# APP_CANCFG register map
Vendor: Texas Instruments
Peripheral module from a debugger description file (folder xwrl64xx).
Registers are 32-bit, read-only, no defined reset value unless marked. A register's access mark holds for its fields unless they carry their own. Offsets are as the file gives them; lines under a group give offsets from that group; [hi:lo] are bit positions; {n}, {i} and the like mark numbered series; 'fields as' and 'values as' point back to an identical list; <NAME> marks a mode.

## APP_CANCFG
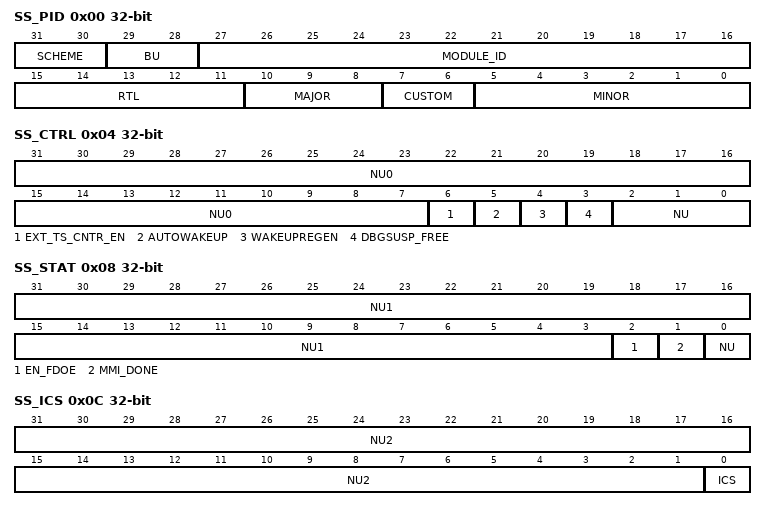
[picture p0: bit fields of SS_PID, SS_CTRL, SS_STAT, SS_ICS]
0x00 SS_PID
  [31:30] SCHEME — PID register scheme
  [29:28] BU — Business Unit: 10 = Processors
  [27:16] MODULE_ID
  [15:11] RTL — RTL revision. Will vary depending on release.
  [10:8] MAJOR — Major revision
  [7:6] CUSTOM
  [5:0] MINOR — Minor revision
0x04 SS_CTRL access per field
  [31:7] NU0 ro — Reserved
  [6] EXT_TS_CNTR_EN rw — External TimeStamp Counter Enable
  [5] AUTOWAKEUP rw — Automatic Wakeup Enable
  [4] WAKEUPREGEN rw — Wakeup Request Enable
  [3] DBGSUSP_FREE rw — 0-Honor Debug Suspend, 1-Disregard debug suspend
  [2:0] NU ro — Reserved
0x08 SS_STAT
  [31:3] NU1 — Reserved
  [2] EN_FDOE — Reflects the value of mcanss_enable_fdoe configuration port x=mcanss_enable_fdoe
  [1] MMI_DONE — 0:Memory Initialization is in progress, 1:Memory Intialization Done
  [0] NU — Reserved
0x0C SS_ICS access per field
  [31:1] NU2 ro — Reserved
  [0] ICS wo — This bit contains the External TimeStamp Counter Overflow Interrupt status. Write '1' to clear bits. (ICS - Interrupt Clear Shadow Register)
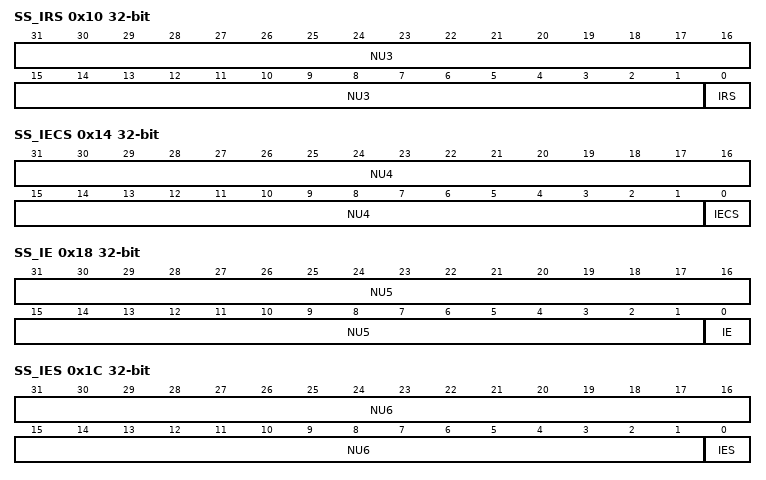
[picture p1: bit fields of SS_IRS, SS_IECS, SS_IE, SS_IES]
0x10 SS_IRS
  [31:1] NU3 — Reserved
  [0] IRS — External TimeStamp Counter Overflow Interrupt status. Read raw interrupt status. (IRS - Interrupt Raw Status Register)
0x14 SS_IECS access per field
  [31:1] NU4 ro — Reserved
  [0] IECS wo — External TimeStamp Counter Overflow Interrupt. Write '1' to clear bits. (IECS - Interrupt Enable Clear Shadow Register)
0x18 SS_IE access per field
  [31:1] NU5 ro — Reserved
  [0] IE rw — External TimeStamp Counter Overflow Interrupt. Write '1' to set interrupt enable. Read returns interrupt enable. (IE - Interrupt Enable Register)
0x1C SS_IES
  [31:1] NU6 — Reserved
  [0] IES — External TimeStamp Counter Overflow Interrupt. Read Enabled Interrupts. (IES - Interrupt Enable Status)
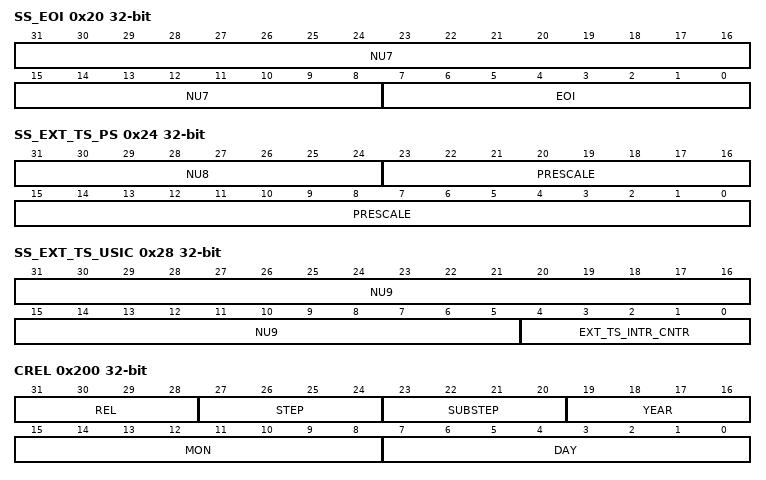
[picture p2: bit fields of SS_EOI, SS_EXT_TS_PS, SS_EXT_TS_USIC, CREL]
0x20 SS_EOI access per field
  [31:8] NU7 ro — Reserved
  [7:0] EOI wo — Write with bit position of targeted interrupt. (E.g. Ext TS is bit 0). Upon write, level interrupt will clear and if unserviced interrupt counter > 1 will issue another pulse interrupt. Field values: ext_ts_eoi(0): EOI value for External TS interrupt mcan_0_eoi(1): EOI value for mcan[0] interrupt mcan_1_eoi(2): EOI value for mcan[1] interrupt (EOI - End Of Interrupt)
0x24 SS_EXT_TS_PS access per field
  [31:24] NU8 ro — Reserved
  [23:0] PRESCALE rw — External Timestamp Prescaler reload value. External Timestamp count rate is host clock rate divided by this value with one exception: a value of 0 has the same effect as 1 .
0x28 SS_EXT_TS_USIC
  [31:5] NU9 — Reserved
  [4:0] EXT_TS_INTR_CNTR — Number of unserviced rollover interrupts. If >1 an EOI write will issue another pulse interrupt (EXT_TS_USIC - External TImeStamp Unserviced Interrupts Counter)
0x200 CREL
  [31:28] REL — Core Release
  [27:24] STEP — Step of Core Release
  [23:20] SUBSTEP — Sub-Step of Core Release
  [19:16] YEAR — Time Stamp Year
  [15:8] MON — Time Stamp Month
  [7:0] DAY — Time Stamp Day
0x204 ENDN
  [31:0] ETV — Endianess test value
0x208 CUST
  [31:0] CUST — Custom
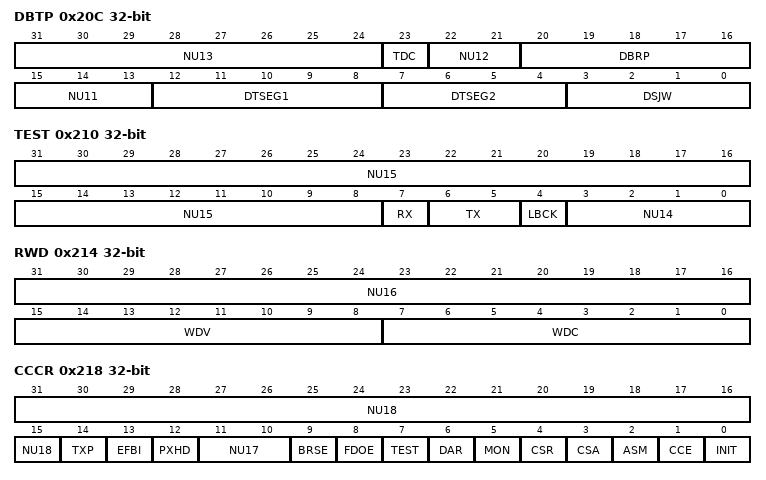
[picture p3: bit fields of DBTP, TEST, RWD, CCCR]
0x20C DBTP access per field
  [31:24] NU13 ro — Reserved
  [23] TDC rw — Transmitter Delay Compensation
  [22:21] NU12 ro — Reserved
  [20:16] DBRP rw — Data Baud Rate Prescaler
  [15:13] NU11 ro — Reserved
  [12:8] DTSEG1 rw — Data time segment before smaple point
  [7:4] DTSEG2 rw — Data time segment after sample point
  [3:0] DSJW rw — Data resynchronization Jump Width
0x210 TEST access per field
  [31:8] NU15 ro — Reserved
  [7] RX ro — Receive Pin
  [6:5] TX rw — Control of Transmit Pin
  [4] LBCK rw — Loop Back Mode
  [3:0] NU14 ro — Reserved
0x214 RWD access per field
  [31:16] NU16 ro — Reserved
  [15:8] WDV ro — Watchdog Value
  [7:0] WDC rw — Watchdog Counter Value
0x218 CCCR access per field
  [31:15] NU18 ro — Reserved
  [14] TXP rw — Transmit Pause
  [13] EFBI rw — Edge Filtering durign Bus Integration
  [12] PXHD rw — Protocol Exception Handling Disable
  [11:10] NU17 ro — Reserved
  [9] BRSE rw — Bit Rate Switch Enable
  [8] FDOE rw — FD Operation Enable
  [7] TEST rw — Test Mode enable
  [6] DAR rw — Disable Automatic Regransmission
  [5] MON rw — Bus Monitoring Mode
  [4] CSR rw — Clock Stop Request
  [3] CSA ro — Clock Stop Acknowledge
  [2] ASM rw — Restriced Operation Mode
  [1] CCE rw — Configuration Change Enable
  [0] INIT rw — Initialization
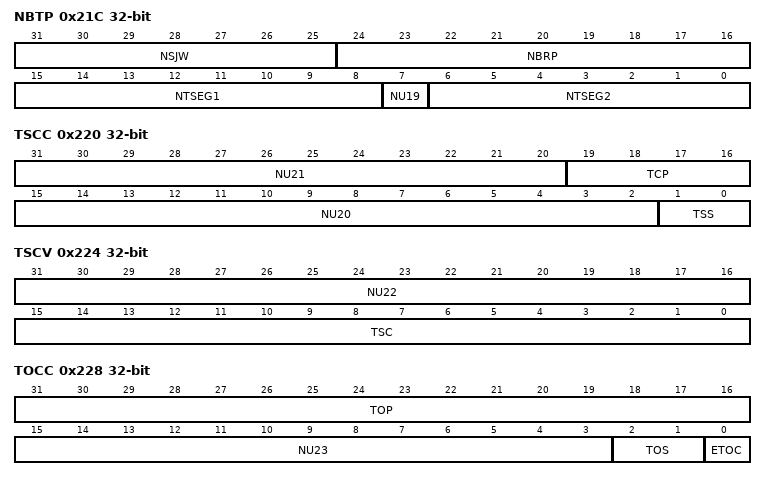
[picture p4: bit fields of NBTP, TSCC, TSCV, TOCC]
0x21C NBTP access per field
  [31:25] NSJW rw — Nominal Resynchronization Jump Width
  [24:16] NBRP rw — Nominal Baud Rate Prescaler
  [15:8] NTSEG1 rw — Nominal Time segment before sample point
  [7] NU19 ro — Reserved
  [6:0] NTSEG2 rw — Nominal Time segment after sample point
0x220 TSCC access per field
  [31:20] NU21 ro — Reserved
  [19:16] TCP rw — Timestamp Counter Prescaler
  [15:2] NU20 ro — Reserved
  [1:0] TSS rw — Timestamp Select
0x224 TSCV access per field
  [31:16] NU22 ro — Reserved
  [15:0] TSC rw — Timestamp Counter
0x228 TOCC access per field
  [31:16] TOP rw — Timeout Period
  [15:3] NU23 ro — Reserved
  [2:1] TOS rw — Timeout Select
  [0] ETOC rw — Enable Timeout Counter
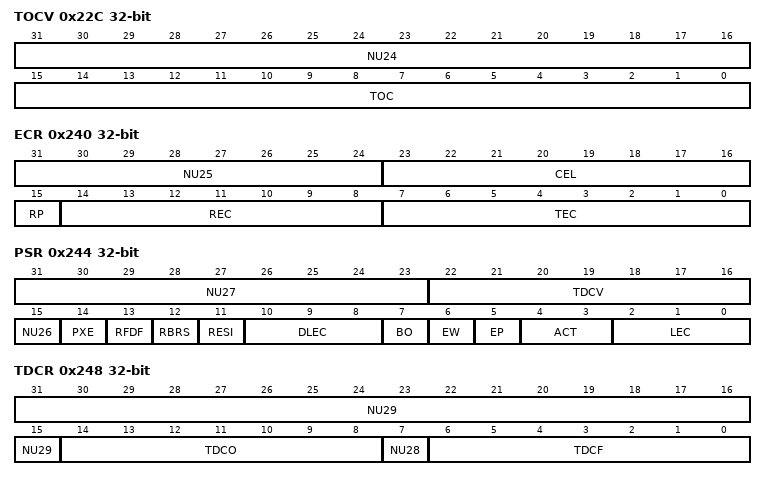
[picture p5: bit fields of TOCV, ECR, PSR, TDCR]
0x22C TOCV access per field
  [31:16] NU24 ro — Reserved
  [15:0] TOC rw — Timeout Counter
{0x230+4i} RES{i:02} (i=0..3)
0x240 ECR
  [31:24] NU25 — Reserved
  [23:16] CEL — CAN Error Logging
  [15] RP — Recieve Error Passive
  [14:8] REC — Recieve Error Counter
  [7:0] TEC — Transmit Error Counter
0x244 PSR
  [31:23] NU27 — Reserved
  [22:16] TDCV — Transmitter Delay Compensation Value
  [15] NU26 — Reserved
  [14] PXE — Protocol Exception Event
  [13] RFDF — Recieved a CAN FD Message
  [12] RBRS — BRS flag of last recieved CAN FD Message
  [11] RESI — ESI flag of last recieved CAN FD Message
  [10:8] DLEC — Data Phase Last Error Code
  [7] BO — Bus_Off status
  [6] EW — Warning Status
  [5] EP — Error Passive
  [4:3] ACT — Activity
  [2:0] LEC — Last Error Code
0x248 TDCR access per field
  [31:15] NU29 ro — Reserved
  [14:8] TDCO rw — Transmitter Delay Compensation Offset
  [7] NU28 ro — Reserved
  [6:0] TDCF rw — Transmitter Delay Compensation Filter Window Length
0x24C RES04
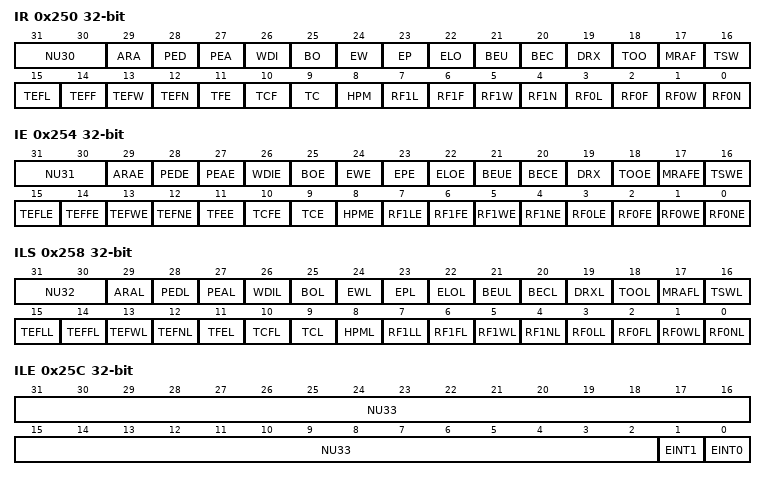
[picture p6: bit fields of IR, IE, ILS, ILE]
0x250 IR access per field
  [31:30] NU30 ro — Reserved
  [29] ARA rw — Access to Reserved Address
  [28] PED rw — Protocol Error in data Phase
  [27] PEA rw — Protocol Error in Arbitration Phase
  [26] WDI rw — Watchdog Interrupt
  [25] BO rw — Bus_Off Status
  [24] EW rw — Warning Status
  [23] EP rw — Error Passive
  [22] ELO rw — Error Logging Overflow
  [21] BEU rw — Bit Error Uncorrected
  [20] BEC rw — Bit Error Corrected
  [19] DRX rw — Message stored to Dedicated Rx Buffer
  [18] TOO rw — Timeout Occurred
  [17] MRAF rw — Message RAM Access Failure
  [16] TSW rw — Timestamp Wraparound
  [15] TEFL rw — Tx Event FIFO Element Lost
  [14] TEFF rw — Tx Event FIFO Full
  [13] TEFW rw — Tx Event FIFO Watermark Reached
  [12] TEFN rw — Tx Event FIFO New Entry
  [11] TFE rw — Tx FIFO Empty
  [10] TCF rw — Transmission Cancellation Finished
  [9] TC rw — Transmission Complete
  [8] HPM rw — High Priority Message
  [7] RF1L rw — Rx FIFO 1 Message Lost
  [6] RF1F rw — Rx FIFO 1 Full
  [5] RF1W rw — Rx FIFO 1 Watermark Reached
  [4] RF1N rw — Rx FIFO 1 New Message
  [3] RF0L rw — Rx FIFO 0 Message Lost
  [2] RF0F rw — Rx FIFO 0 Full
  [1] RF0W rw — Rx FIFO 0 Watermark Reached
  [0] RF0N rw — Rx FIFO 0 New Message
0x254 IE access per field
  [31:30] NU31 ro — Reserved
  [29] ARAE rw — Accees to Reserve Address Interrupt Enable
  [28] PEDE rw — Protocol Error in Data Phase Interrupt Enable
  [27] PEAE rw — Protocol Error in Arbitration Phase Interrupt Enable
  [26] WDIE rw — Watchdog Interrupt Enable
  [25] BOE rw — Bus_Off Status Interrupt Enable
  [24] EWE rw — Warning Status Interrupt Enable
  [23] EPE rw — Error Passive Interrupt Enable
  [22] ELOE rw — Error Logging Overflow Interrupt Enable
  [21] BEUE rw — Bit Error Uncorrected Interrupt Enable
  [20] BECE rw — Bit Error Corrected Interrupt Enable
  [19] DRX rw — Message stored to Dedicated Rx Buffer Interrupt Enable
  [18] TOOE rw — Timeout Occurred Interrupt Enable
  [17] MRAFE rw — Message RAM Access Failure Interrupt Enable
  [16] TSWE rw — Timestamp Wraparound Interrupt Enable
  [15] TEFLE rw — Tx Event FIFO Event Lost Interrupt Enable
  [14] TEFFE rw — Tx Event FIFO Full Interrupt Enable
  [13] TEFWE rw — Tx Event FIFO Watermark Reached Interrupt enable
  [12] TEFNE rw — Tx Event FIFO New Entry Interrupt Enable
  [11] TFEE rw — Tx FIFO Empty Interrupt Enable
  [10] TCFE rw — Transmission Cancellation Finishied Interrupt Enable
  [9] TCE rw — Transmission Completed Interrupt Enable
  [8] HPME rw — High Priority message Interrupt Enable
  [7] RF1LE rw — rx FIFO 1 Message Lost Interrupt Enable
  [6] RF1FE rw — Rx FIFO 1 Full Interrupt Enable
  [5] RF1WE rw — Rx FIFO 1 Watermark Reached Interrupt Enable
  [4] RF1NE rw — Rx FIFO 1 New Message Interrupt Enable
  [3] RF0LE rw — Rx FIFO 0 Message Lost Interrupt Enable
  [2] RF0FE rw — Rx FIFO 0 Full Interrupt Enable
  [1] RF0WE rw — Rx FIFO 0 Watermark Reached Interrupt Enable
  [0] RF0NE rw — Rx FIFO 0 New Message Interrupt Enable
0x258 ILS access per field
  [31:30] NU32 ro — Reserved
  [29] ARAL rw — Accees to Reserve Address Interrupt Line
  [28] PEDL rw — Protocol Error in Data Phase Interrupt Line
  [27] PEAL rw — Protocol Error in Arbitration Phase Interrupt Line
  [26] WDIL rw — Watchdog Interrupt Line
  [25] BOL rw — Bus_Off Status Interrupt Line
  [24] EWL rw — Warning Status Interrupt Line
  [23] EPL rw — Error Passive Interrupt Line
  [22] ELOL rw — Error Logging Overflow Interrupt Line
  [21] BEUL rw — Bit Error Uncorrected Interrupt Line
  [20] BECL rw — Bit Error Corrected Interrupt Line
  [19] DRXL rw — Message stored to Dedicated Rx Buffer Interrupt Line
  [18] TOOL rw — Timeout Occurred Interrupt Line
  [17] MRAFL rw — Message RAM Access Failure Interrupt Line
  [16] TSWL rw — Timestamp Wraparound Interrupt Line
  [15] TEFLL rw — Tx Event FIFO Event Lost Interrupt Line
  [14] TEFFL rw — Tx Event FIFO Full Interrupt Line
  [13] TEFWL rw — Tx Event FIFO Watermark Reached Interrupt Line
  [12] TEFNL rw — Tx Event FIFO New Entry Interrupt Line
  [11] TFEL rw — Tx FIFO Empty Interrupt Line
  [10] TCFL rw — Transmission Cancellation Finishied Interrupt Line
  [9] TCL rw — Transmission Completed Interrupt Line
  [8] HPML rw — High Priority message Interrupt Line
  [7] RF1LL rw — rx FIFO 1 Message Lost Interrupt Line
  [6] RF1FL rw — Rx FIFO 1 Full Interrupt Line
  [5] RF1WL rw — Rx FIFO 1 Watermark Reached Interrupt Line
  [4] RF1NL rw — Rx FIFO 1 New Message Interrupt Line
  [3] RF0LL rw — Rx FIFO 0 Message Lost Interrupt Line
  [2] RF0FL rw — Rx FIFO 0 Full Interrupt Line
  [1] RF0WL rw — Rx FIFO 0 Watermark Reached Interrupt Line
  [0] RF0NL rw — Rx FIFO 0 New Message Interrupt Line
0x25C ILE access per field
  [31:2] NU33 ro — Reserved
  [1] EINT1 rw — Enable Interrupt Line 1
  [0] EINT0 rw — Enable Interrupt Line 0
{0x24C+4i} RES{i:02} (i=5..12)
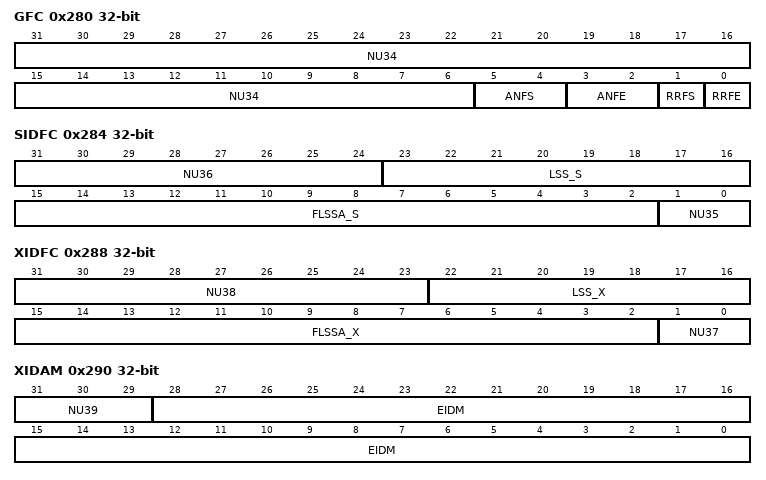
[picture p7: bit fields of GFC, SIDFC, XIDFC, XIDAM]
0x280 GFC access per field
  [31:6] NU34 ro — Reserved
  [5:4] ANFS rw — Accept Non-matching Frames Standard
  [3:2] ANFE rw — Accept Non-matching Frames Extended
  [1] RRFS rw — reject Remote Frames Standard
  [0] RRFE rw — reject Remote Frames Extended
0x284 SIDFC access per field
  [31:24] NU36 ro — Reserved
  [23:16] LSS_S rw — List Size Standard
  [15:2] FLSSA_S rw — Filter List Standard Start Address
  [1:0] NU35 ro — Reserved
0x288 XIDFC access per field
  [31:23] NU38 ro — Reserved
  [22:16] LSS_X rw — List Size Standard
  [15:2] FLSSA_X rw — Filter List Standard Start Address
  [1:0] NU37 ro — Reserved
0x28C RES13
0x290 XIDAM access per field
  [31:29] NU39 ro — Reserved
  [28:0] EIDM rw — Extended ID Mask
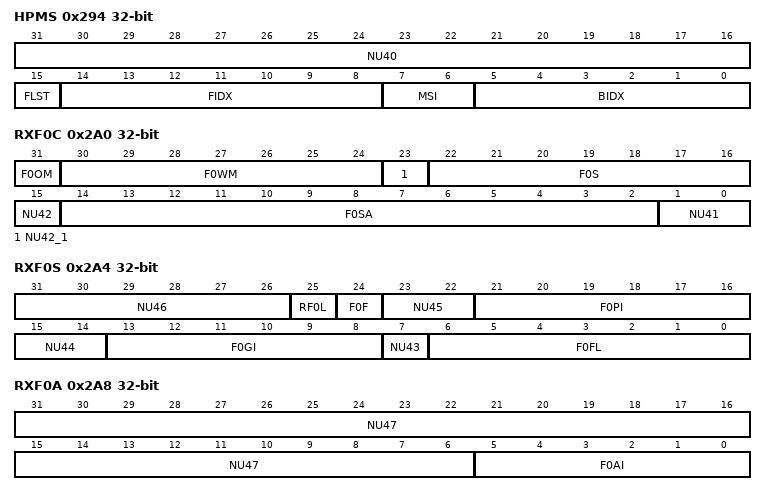
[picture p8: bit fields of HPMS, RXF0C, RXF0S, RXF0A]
0x294 HPMS
  [31:16] NU40 — Reserved
  [15] FLST — Filter List
  [14:8] FIDX — Filter Index
  [7:6] MSI — Message Storeage Indicator
  [5:0] BIDX — Buffer Index
0x298 NDAT1 rw
  [31:0] ND0_31 — New Data 0-31
0x29C NDAT2 rw
  [31:0] ND32_63 — New Data 32-63
0x2A0 RXF0C access per field
  [31] F0OM rw — Rx FIFO 0 Operation Mode
  [30:24] F0WM rw — Rx FIFO 0 Watermark
  [23] NU42_1 ro — Reserved
  [22:16] F0S rw — Rx FIFO 0 Size
  [15] NU42 ro — Reserved
  [14:2] F0SA rw — Rx FIFO 0 Start Address
  [1:0] NU41 ro — Reserved
0x2A4 RXF0S
  [31:26] NU46 — Reserved
  [25] RF0L — Rx FIFO 0 Message Lost
  [24] F0F — Rx FIFO 0 Full
  [23:22] NU45 — Reserved
  [21:16] F0PI — Rx FIFO 0 Put Index
  [15:14] NU44 — Reserved
  [13:8] F0GI — Rx FIFO 0 Get Index
  [7] NU43 — Reserved
  [6:0] F0FL — Rx FIFO 0 Fill Level
0x2A8 RXF0A access per field
  [31:6] NU47 ro — Reserved
  [5:0] F0AI rw — Rx FIFO 0 Acknowledge Index
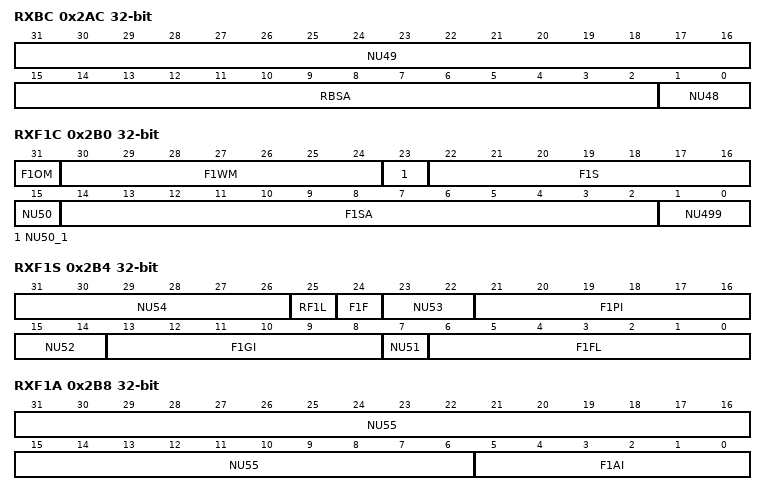
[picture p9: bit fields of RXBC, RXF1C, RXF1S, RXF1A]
0x2AC RXBC access per field
  [31:16] NU49 ro — Reserved
  [15:2] RBSA rw — Rx Buffer Start Address
  [1:0] NU48 ro — Reserved
0x2B0 RXF1C access per field
  [31] F1OM rw — Rx FIFO 0 Operation Mode
  [30:24] F1WM rw — Rx FIFO 0 Watermark
  [23] NU50_1 ro — Reserved
  [22:16] F1S rw — Rx FIFO 0 Size
  [15] NU50 ro — Reserved
  [14:2] F1SA rw — Rx FIFO 0 Start Address
  [1:0] NU499 ro — Reserved
0x2B4 RXF1S
  [31:26] NU54 — Reserved
  [25] RF1L — Rx FIFO 0 Message Lost
  [24] F1F — Rx FIFO 0 Full
  [23:22] NU53 — Reserved
  [21:16] F1PI — Rx FIFO 0 Put Index
  [15:14] NU52 — Reserved
  [13:8] F1GI — Rx FIFO 0 Get Index
  [7] NU51 — Reserved
  [6:0] F1FL — Rx FIFO 0 Fill Level
0x2B8 RXF1A access per field
  [31:6] NU55 ro — Reserved
  [5:0] F1AI rw — Rx FIFO 0 Acknowledge Index
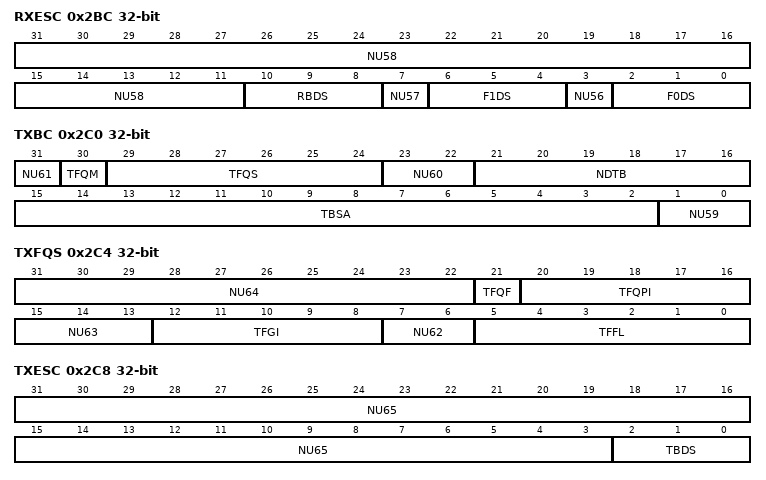
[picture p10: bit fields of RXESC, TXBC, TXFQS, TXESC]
0x2BC RXESC access per field
  [31:11] NU58 ro — Reserved
  [10:8] RBDS rw — Rx Buffer data Field Size
  [7] NU57 ro — Reserved
  [6:4] F1DS rw — Rx FIFO 1 Data Field Size
  [3] NU56 ro — Reserved
  [2:0] F0DS rw — Rx FIFO 0 Data Field Size
0x2C0 TXBC
  [31] NU61 — Reserved
  [30] TFQM — Tx FIFO/Queue Mode
  [29:24] TFQS — Transmit FIFO/Queue Size
  [23:22] NU60 — Reserved
  [21:16] NDTB — Number of Dedicated Transmit Buffers
  [15:2] TBSA — Tx Buffers Start Address
  [1:0] NU59 — Reserved
0x2C4 TXFQS
  [31:22] NU64 — Reserved
  [21] TFQF — Tx FIFO/Queue Full
  [20:16] TFQPI — Tx FIFO/Queue Put Index
  [15:13] NU63 — Reserved
  [12:8] TFGI — Tx Queue Get Index
  [7:6] NU62 — Reserved
  [5:0] TFFL — Tx FIFO Free Level
0x2C8 TXESC access per field
  [31:3] NU65 ro — Reserved
  [2:0] TBDS rw — Tx Buffer Data Field Size
0x2CC TXBRP
  [31:0] TRP — Transmission Request Pending
0x2D0 TXBAR access not given
  [31:0] AR — Add request
0x2D4 TXBCR access not given
  [31:0] CR — Cancellation Request
0x2D8 TXBTO
  [31:0] TO — Transmission Occurred
0x2DC TXBCF
  [31:0] CF — Cancellation Finished
0x2E0 TXBTIE rw
  [31:0] TIE — Transmission Interrupt Enable
0x2E4 TXBCIE rw
  [31:0] CFIE — Cancellation Finished Interrupt Enable
0x2E8 RES14
0x2EC RES15
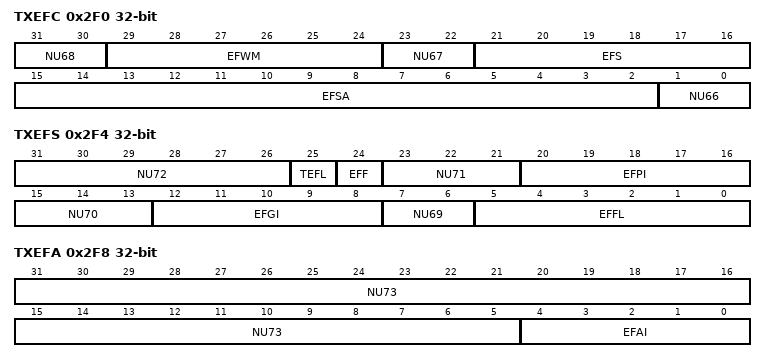
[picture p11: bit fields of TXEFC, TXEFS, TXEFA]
0x2F0 TXEFC access per field
  [31:30] NU68 ro — Reserved
  [29:24] EFWM rw — Event FIFO Watermark
  [23:22] NU67 ro — Reserved
  [21:16] EFS rw — Event FIFO Size
  [15:2] EFSA rw — Event FIFO Start Address
  [1:0] NU66 ro — Reserved
0x2F4 TXEFS
  [31:26] NU72 — Reserved
  [25] TEFL — Tx Event FIFO Element Lost
  [24] EFF — Event FIFO Full
  [23:21] NU71 — Reserved
  [20:16] EFPI — Event FIFO Put Index
  [15:13] NU70 — Reserved
  [12:8] EFGI — Event FIFO Get Index
  [7:6] NU69 — Reserved
  [5:0] EFFL — Event FIFO FIll Level
0x2F8 TXEFA
  [31:5] NU73 — Reserved
  [4:0] EFAI — Event FIFO Acknowledge Index
0x2FC RES16
